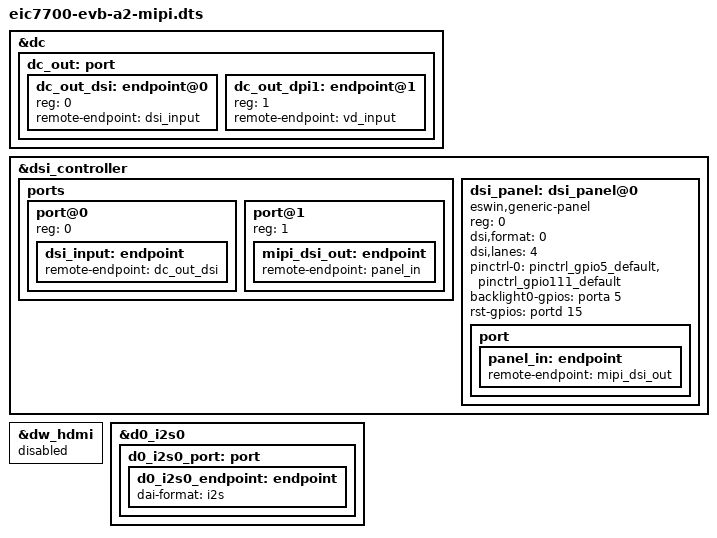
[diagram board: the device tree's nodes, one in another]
// SPDX-License-Identifier: GPL-2.0
/*
 * Device Tree file for Eswin EIC7700 SoC.
 *
 * Copyright 2024, Beijing ESWIN Computing Technology Co., Ltd.. All rights reserved.
 * SPDX-License-Identifier: GPL-2.0
 *
 * This program is free software: you can redistribute it and/or modify
 * it under the terms of the GNU General Public License as published by
 * the Free Software Foundation, version 2.
 *
 * This program is distributed in the hope that it will be useful,
 * but WITHOUT ANY WARRANTY; without even the implied warranty of
 * MERCHANTABILITY or FITNESS FOR A PARTICULAR PURPOSE.  See the
 * GNU General Public License for more details.
 *
 * You should have received a copy of the GNU General Public License
 * along with this program.  If not, see <https://www.gnu.org/licenses/>.
 */

/dts-v1/;

#include "eic7700-evb-a2.dtsi"

/* Clock frequency (in Hz) of the PCB crystal for rtcclk */

&dc {
	status = "okay";
	dc_out: port {
		#address-cells = <1>;
		#size-cells = <0>;
		dc_out_dsi: endpoint@0 {
			reg = <0>;
			remote-endpoint = <&dsi_input>;
		};
		dc_out_dpi1: endpoint@1 {
			reg = <1>;
			remote-endpoint = <&vd_input>;
		};
	};
};

&dsi_controller {
	status = "okay";
	ports {
		#address-cells = <1>;
		#size-cells = <0>;
		port@0 {
			#address-cells = <1>;
			#size-cells = <0>;
			reg = <0>;
			dsi_input: endpoint {
				remote-endpoint = <&dc_out_dsi>;
			};
		};
		port@1 {
			#address-cells = <1>;
			#size-cells = <0>;
			reg = <1>;
			mipi_dsi_out: endpoint {
				remote-endpoint = <&panel_in>;
			};
		};
	};

	dsi_panel:dsi_panel@0 {
		compatible = "eswin,generic-panel";
		reg = <0>;
		dsi,format = <0>; //RGB888:0, RGB666:1, RGB565:3
		dsi,lanes = <4>;
		port {
			panel_in: endpoint {
				remote-endpoint = <&mipi_dsi_out>;
			};
		};
	};
};

&dsi_panel {
	status = "okay";
	pinctrl-names = "default";
	pinctrl-0 = <&pinctrl_gpio5_default &pinctrl_gpio111_default>;
	backlight0-gpios = <&porta 5 GPIO_ACTIVE_HIGH>;
	rst-gpios = <&portd 15 GPIO_ACTIVE_HIGH>;
};

&dw_hdmi {
	status = "disabled";
};

&d0_i2s0 {
	status = "okay";
	d0_i2s0_port: port {
		d0_i2s0_endpoint: endpoint {
			dai-format = "i2s";
		};
	};
};
